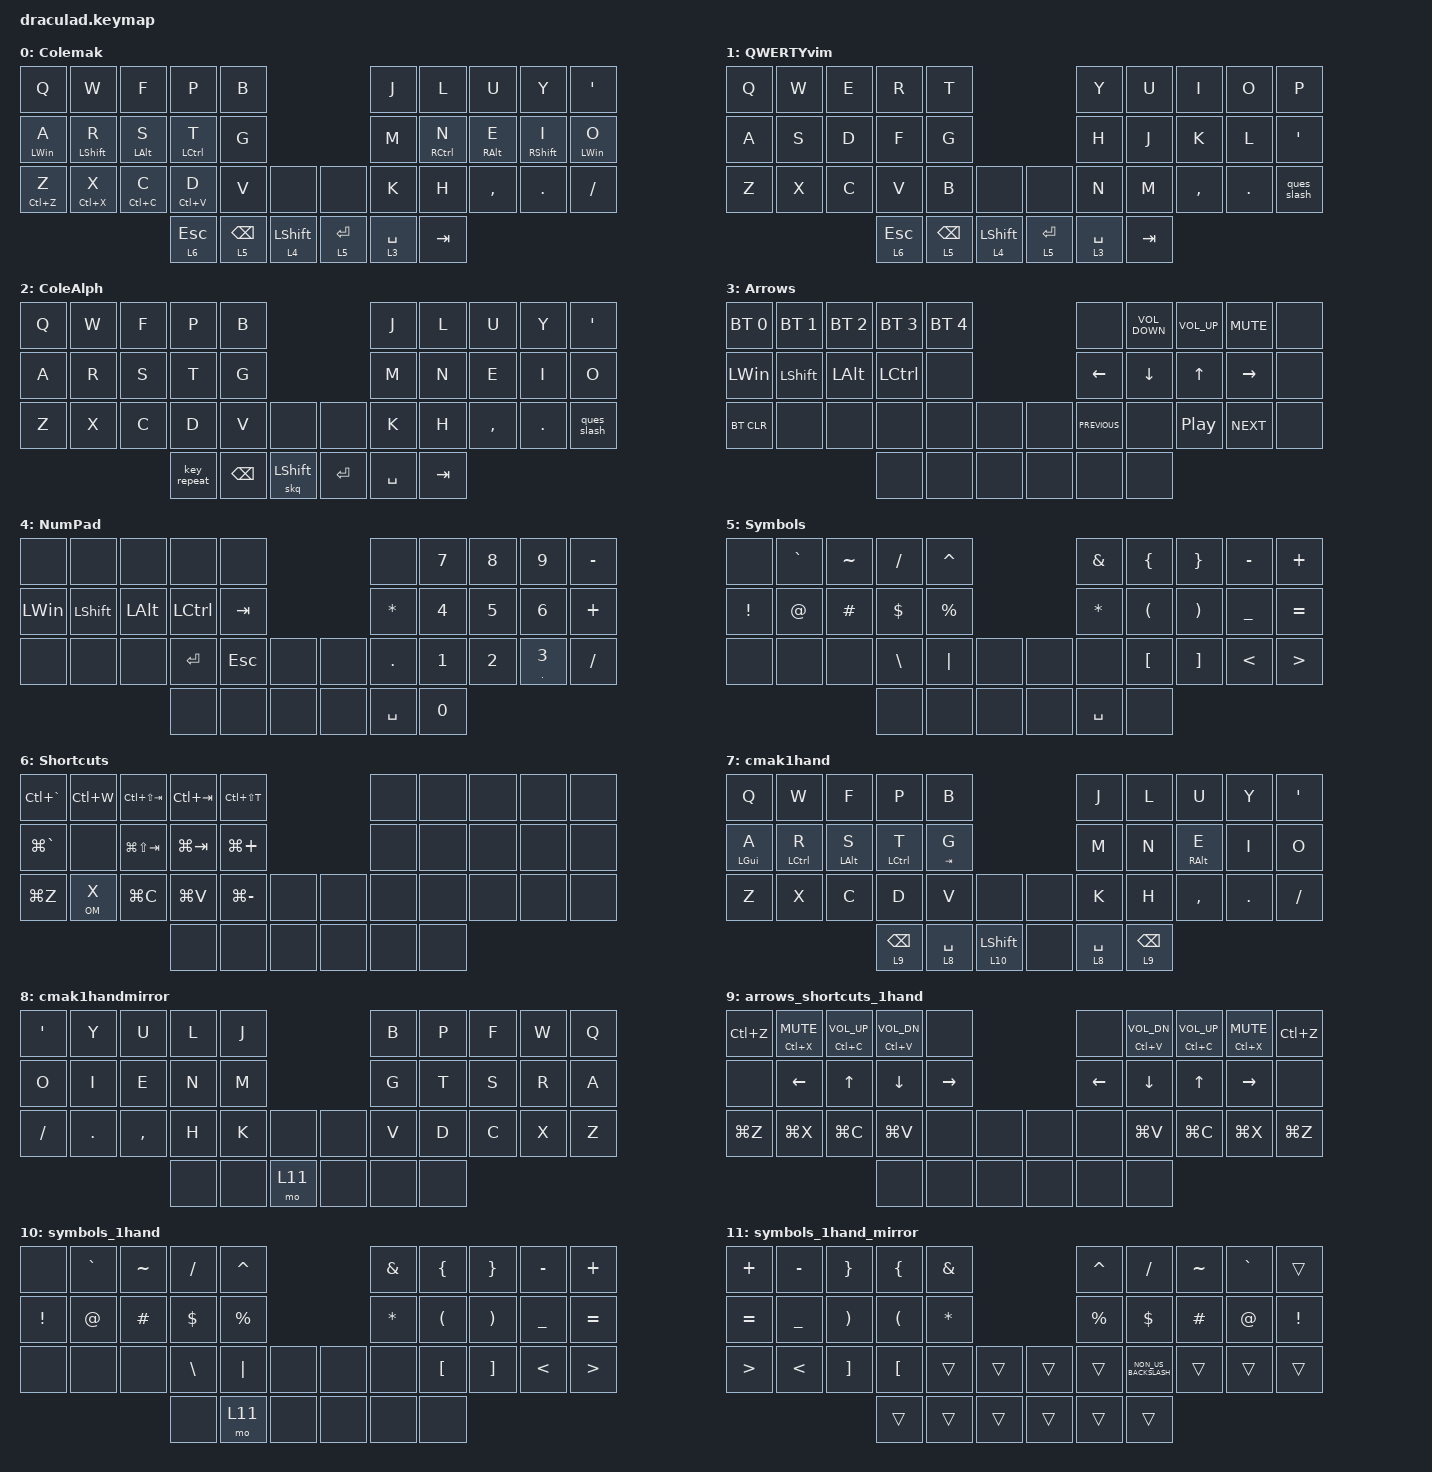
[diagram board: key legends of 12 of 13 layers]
/*
 * Copyright (c) 2020 The ZMK Contributors
 *
 * SPDX-License-Identifier: MIT
 */

#include <behaviors.dtsi>
#include <dt-bindings/zmk/bt.h>
#include <dt-bindings/zmk/keys.h>

/ {
    combos {
        compatible = "zmk,combos";

        combo_enter {
            timeout-ms = <50>;
            key-positions = <1 2>;
            bindings = <&kp ENTER>;
            layers = <0 1 7 12>;
        };

        combo_colon {
            timeout-ms = <50>;
            key-positions = <29 30>;
            bindings = <&kp COLON>;
            layers = <0 1 12>;
        };

        combo_semicolon {
            bindings = <&kp SEMICOLON>;
            key-positions = <30 31>;
            layers = <0 1 12>;
        };

        toggle1hand {
            bindings = <&tog 7>;
            key-positions = <0 1>;
            layers = <0 7>;
        };

        shift_enter {
            bindings = <&kp LS(ENTER)>;
            key-positions = <2 3>;
            layers = <0 1 12>;
        };

        canary {
            bindings = <&tog 12>;
            key-positions = <5 6>;
            layers = <0 12>;
        };

        enter_right_hand {
            bindings = <&kp ENTER>;
            key-positions = <7 8>;
            layers = <7>;
        };

        toggle_qwerty {
            bindings = <&tog 1>;
            key-positions = <3 4>;
            layers = <0 1>;
        };
    };
};

/ {
    macros {
        OM: macro_os_modifier {
            label = "OS_MODIFIER";
            compatible = "zmk,behavior-macro-one-param";
            #binding-cells = <1>;
            bindings = 
                <&macro_press &kp LEFT_GUI>,
                <&macro_param_1to1 &macro_tap &kp MACRO_PLACEHOLDER>,
                <&macro_release &kp LEFT_GUI>;
        };
    };
};

/ {
    behaviors {
        hml: hml {
            compatible = "zmk,behavior-hold-tap";
            label = "HOMEROW_MODS_LEFT";
            bindings = <&kp>, <&kp>;

            #binding-cells = <2>;
            tapping-term-ms = <200>;

            //            hold-trigger-key-positions = <39 40 41 30 18 6 7 19 31 32 20 8 9 21 33 34 22 10 11 23 35 2 14 13 37 38 15 16>;

            flavor = "tap-preferred";
            require-prior-idle-ms = <150>;
        };

        hmr: hmr {
            compatible = "zmk,behavior-hold-tap";
            label = "HOMEROW_MODS_RIGHT";
            bindings = <&kp>, <&kp>;

            #binding-cells = <2>;
            tapping-term-ms = <200>;

            //            hold-trigger-key-positions = <12 0 1 2 3 4 5 12 13 14 15 16 17 24 25 26 27 28 29 36 37 38 20 19 21>;

            flavor = "tap-preferred";
            require-prior-idle-ms = <150>;
        };

        lp: lp {
            compatible = "zmk,behavior-hold-tap";
            label = "LONG_PRESS";
            bindings = <&kp>, <&kp>;

            #binding-cells = <2>;
            tapping-term-ms = <200>;
            flavor = "tap-preferred";
            require-prior-idle-ms = <150>;
        };

        skq: skq {
            compatible = "zmk,behavior-sticky-key";
            label = "sticky_key_quick_release";
            #binding-cells = <1>;
            bindings = <&kp>;
            release-after-ms = <1000>;
            quick-release;
            ignore-modifiers;
        };

        mo_ss: behavior_mo_ss {
            compatible = "zmk,behavior-hold-tap";
            label = "mo_ss";
            #binding-cells = <2>;
            bindings = <&mo>, <&skq>;

            tapping-term-ms = <200>;
            flavor = "tap-preferred";
        };

        col_semi: colon_semicolon {
            compatible = "zmk,behavior-mod-morph";
            #binding-cells = <0>;
            bindings = <&kp COLON>, <&kp SEMI>;

            mods = <(MOD_LSFT|MOD_RSFT)>;
        };

        ques_slash: ques_slash {
            compatible = "zmk,behavior-mod-morph";
            #binding-cells = <0>;
            bindings = <&kp QUESTION>, <&kp SLASH>;

            mods = <(MOD_LSFT|MOD_RSFT)>;
        };
    };

    keymap {
        compatible = "zmk,keymap";

        default_layer {
            label = "Colemak";
            bindings = <
&kp Q            &kp W              &kp F            &kp P                &kp B                                          &kp J        &kp L                 &kp U             &kp Y               &kp SINGLE_QUOTE
&hml LEFT_WIN A  &hml LEFT_SHIFT R  &hml LEFT_ALT S  &hml LEFT_CONTROL T  &kp G                                          &kp M        &hmr RIGHT_CONTROL N  &hmr RIGHT_ALT E  &hmr RIGHT_SHIFT I  &hmr LEFT_WIN O
&lp LC(Z) Z      &lp LC(X) X        &lp LC(C) C      &lp LC(V) D          &kp V            &none              &none      &kp K        &kp H                 &kp COMMA         &kp PERIOD          &kp SLASH
                                                     &lt 6 ESC            &lt 5 BACKSPACE  &mo_ss 4 LSHIFT    &lt 5 RET  &lt 3 SPACE  &kp TAB
            >;
        };

        qwerty {
            label = "QWERTYvim";
            bindings = <
&kp Q  &kp W  &kp E  &kp R      &kp T                                          &kp Y        &kp U    &kp I      &kp O    &kp P
&kp A  &kp S  &kp D  &kp F      &kp G                                          &kp H        &kp J    &kp K      &kp L    &kp SINGLE_QUOTE
&kp Z  &kp X  &kp C  &kp V      &kp B            &none              &none      &kp N        &kp M    &kp COMMA  &kp DOT  &ques_slash
                     &lt 6 ESC  &lt 5 BACKSPACE  &mo_ss 4 LSHIFT    &lt 5 RET  &lt 3 SPACE  &kp TAB
            >;
        };

        colemak_alpha {
            label = "ColeAlph";
            bindings = <
&kp Q  &kp W  &kp F  &kp P        &kp B                                  &kp J      &kp L    &kp U      &kp Y       &kp SINGLE_QUOTE
&kp A  &kp R  &kp S  &kp T        &kp G                                  &kp M      &kp N    &kp E      &kp I       &kp O
&kp Z  &kp X  &kp C  &kp D        &kp V          &none          &none    &kp K      &kp H    &kp COMMA  &kp PERIOD  &ques_slash
                     &key_repeat  &kp BACKSPACE  &skq LSHIFT    &kp RET  &kp SPACE  &kp TAB
            >;
        };

        arrows_layer {
            label = "Arrows";
            bindings = <
&bt BT_SEL 0  &bt BT_SEL 1    &bt BT_SEL 2  &bt BT_SEL 3      &bt BT_SEL 4                  &none           &kp C_VOLUME_DOWN  &kp C_VOLUME_UP   &kp C_MUTE       &none
&kp LEFT_WIN  &kp LEFT_SHIFT  &kp LEFT_ALT  &kp LEFT_CONTROL  &none                         &kp LEFT_ARROW  &kp DOWN_ARROW     &kp UP_ARROW      &kp RIGHT_ARROW  &none
&bt BT_CLR    &none           &none         &none             &none         &none    &none  &kp C_PREVIOUS  &none              &kp C_PLAY_PAUSE  &kp C_NEXT       &none
                                            &none             &none         &none    &none  &none           &none
            >;
        };

        numpad_layer {
            label = "NumPad";
            bindings = <
&none         &none           &none         &none             &none                    &none         &kp N7  &kp N8  &kp N9         &kp MINUS
&kp LEFT_WIN  &kp LEFT_SHIFT  &kp LEFT_ALT  &kp LEFT_CONTROL  &kp TAB                  &kp ASTERISK  &kp N4  &kp N5  &kp N6         &kp PLUS
&none         &none           &none         &kp RET           &kp ESC  &none    &none  &kp PERIOD    &kp N1  &kp N2  &lp PERIOD N3  &kp SLASH
                                            &none             &none    &none    &none  &kp SPACE     &kp N0
            >;
        };

        symbols {
            label = "Symbols";
            bindings = <
&none            &kp GRAVE    &kp TILDE  &kp SLASH      &kp CARET                    &kp AMPERSAND  &kp LEFT_BRACE        &kp RIGHT_BRACE        &kp MINUS       &kp PLUS
&kp EXCLAMATION  &kp AT_SIGN  &kp POUND  &kp DOLLAR     &kp PERCENT                  &kp ASTERISK   &kp LEFT_PARENTHESIS  &kp RIGHT_PARENTHESIS  &kp UNDERSCORE  &kp EQUAL
&none            &none        &none      &kp BACKSLASH  &kp PIPE     &none    &none  &none          &kp LEFT_BRACKET      &kp RIGHT_BRACKET      &kp LESS_THAN   &kp GREATER_THAN
                                         &none          &none        &none    &none  &kp SPACE      &none
            >;
        };

        shortcut {
            label = "Shortcuts";
            bindings = <
&kp LC(GRAVE)  &kp LC(W)  &kp LC(LS(TAB))  &kp LC(TAB)  &kp LC(LS(T))                  &none  &none  &none  &none  &none
&kp LG(GRAVE)  &none      &kp LG(LS(TAB))  &kp LG(TAB)  &kp LG(PLUS)                   &none  &none  &none  &none  &none
&kp LG(Z)      &OM X  &kp LG(C)        &kp LG(V)    &kp LG(MINUS)  &none    &none  &none  &none  &none  &none  &none
                                           &none        &none          &none    &none  &none  &none
            >;
        };

        cmak1hand {
            bindings = <
&kp Q            &kp W                &kp F            &kp P                &kp B                                       &kp J        &kp L            &kp U             &kp Y    &kp APOS
&hml LEFT_GUI A  &hml LEFT_CONTROL R  &hml LEFT_ALT S  &hml LEFT_CONTROL T  &mt TAB G                                   &kp M        &kp N            &hmr RIGHT_ALT E  &kp I    &kp O
&kp Z            &kp X                &kp C            &kp D                &kp V        &none                   &none  &kp K        &kp H            &kp COMMA         &kp DOT  &kp FSLH
                                                       &lt 9 BACKSPACE      &lt 8 SPACE  &mo_ss 10 LEFT_SHIFT    &none  &lt 8 SPACE  &lt 9 BACKSPACE
            >;
        };

        cmak1handmirror {
            bindings = <
&kp APOS  &kp Y    &kp U      &kp L  &kp J                   &kp B  &kp P  &kp F  &kp W  &kp Q
&kp O     &kp I    &kp E      &kp N  &kp M                   &kp G  &kp T  &kp S  &kp R  &kp A
&kp FSLH  &kp DOT  &kp COMMA  &kp H  &kp K  &none     &none  &kp V  &kp D  &kp C  &kp X  &kp Z
                              &none  &none  &mo 11    &none  &none  &none
            >;
        };

        arrows_shortcuts_1hand {
            bindings = <
&kp LC(Z)  &mt LC(X) K_MUTE  &mt LC(C) C_VOLUME_UP  &mt LC(V) C_VOL_DN  &none                      &none           &mt LC(V) C_VOL_DN  &mt LC(C) C_VOL_UP  &mt LC(X) K_MUTE  &kp LC(Z)
&none      &kp LEFT_ARROW    &kp UP_ARROW           &kp DOWN            &kp RIGHT                  &kp LEFT_ARROW  &kp DOWN            &kp UP              &kp RIGHT         &none
&kp LG(Z)  &kp LG(X)         &kp LG(C)              &kp LG(V)           &none      &none    &none  &none           &kp LG(V)           &kp LG(C)           &kp LG(X)         &kp LG(Z)
                                                    &none               &none      &none    &none  &none           &none
            >;
        };

        symbols_1hand {
            bindings = <
&none            &kp GRAVE    &kp TILDE  &kp FSLH    &kp CARET                    &kp AMPERSAND  &kp LEFT_BRACE        &kp RIGHT_BRACE        &kp MINUS       &kp PLUS
&kp EXCLAMATION  &kp AT_SIGN  &kp HASH   &kp DOLLAR  &kp PERCENT                  &kp ASTERISK   &kp LEFT_PARENTHESIS  &kp RIGHT_PARENTHESIS  &kp UNDERSCORE  &kp EQUAL
&none            &none        &none      &kp BSLH    &kp PIPE     &none    &none  &none          &kp LBKT              &kp RBKT               &kp LESS_THAN   &kp GREATER_THAN
                                         &none       &mo 11       &none    &none  &none          &none
            >;
        };

        symbols_1hand_mirror {
            bindings = <
&kp PLUS          &kp MINUS       &kp RIGHT_BRACE        &kp LEFT_BRACE        &kp AMPERSAND                    &kp CARET    &kp SLASH             &kp TILDE  &kp GRAVE    &trans
&kp EQUAL         &kp UNDERSCORE  &kp RIGHT_PARENTHESIS  &kp LEFT_PARENTHESIS  &kp ASTERISK                     &kp PERCENT  &kp DOLLAR            &kp HASH   &kp AT_SIGN  &kp EXCLAMATION
&kp GREATER_THAN  &kp LESS_THAN   &kp RIGHT_BRACKET      &kp LEFT_BRACKET      &trans         &trans    &trans  &trans       &kp NON_US_BACKSLASH  &trans     &trans       &trans
                                                         &trans                &trans         &trans    &trans  &trans       &trans
            >;
        };

        canary {
            bindings = <
&kp W            &kp L              &kp Y            &kp P         &kp B                                      &kp Z            &kp F                 &kp O             &kp U              &kp APOS
&hml LEFT_WIN C  &hml LEFT_SHIFT R  &hml LEFT_ALT S  &hml LCTRL T  &kp G                                      &kp M            &hmr RIGHT_CONTROL N  &hmr RIGHT_ALT E  &hmr LEFT_SHIFT I  &hmr RIGHT_GUI A
&kp Q            &kp J              &kp V            &kp D         &kp K        &none                  &none  &kp X            &kp H                 &kp COMMA         &kp DOT            &kp FSLH
                                                     &lt 6 ESCAPE  &lt 5 SPACE  &mo_ss 4 LEFT_SHIFT    &none  &lt 3 BACKSPACE  &kp TAB
            >;
        };
    };
};
